# ATA5272 device description
Architecture: AVR8; Family: megaAVR
Registers are 8-bit, access not given, no defined reset value unless marked. A register's access mark holds for its fields unless they carry their own. Offsets are from the block's base; [hi:lo] are bit positions.

## FUSE
Instances: FUSE 0 in fuses
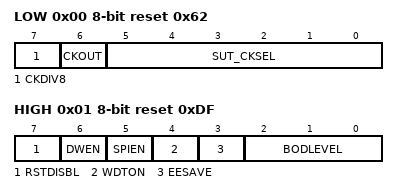
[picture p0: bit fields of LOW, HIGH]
0x00 LOW reset 0x62
  [7] CKDIV8 — Divide clock by 8 internally
  [6] CKOUT — Clock output on PORTB5
  [5:0] SUT_CKSEL — Select Clock source
    0=EXT_CLOCK_START_UP_TIME_PWRDWN_RESET_6_CK_14_CK_0_MS; 16=EXT_CLOCK_START_UP_TIME_PWRDWN_RESET_6_CK_14_CK_4_MS; 32=EXT_CLOCK_START_UP_TIME_PWRDWN_RESET_6_CK_14_CK_64_MS; 2=INT_RC_OSC_8_MHZ_START_UP_TIME_PWRDWN_RESET_6_CK_14_CK_0_MS; 18=INT_RC_OSC_8_MHZ_START_UP_TIME_PWRDWN_RESET_6_CK_14_CK_4_MS; 34=INT_RC_OSC_8_MHZ_START_UP_TIME_PWRDWN_RESET_6_CK_14_CK_64_MS; 3=WD_OSC_128_KHZ_START_UP_TIME_PWRDWN_RESET_6_CK_14_CK_0_MS; 19=WD_OSC_128_KHZ_START_UP_TIME_PWRDWN_RESET_6_CK_14_CK_4_MS; 35=WD_OSC_128_KHZ_START_UP_TIME_PWRDWN_RESET_6_CK_14_CK_64_MS; 4=EXT_LOW_FREQ_CRYSTAL_START_UP_TIME_PWRDWN_RESET_1024_CK_4_MS; 20=EXT_LOW_FREQ_CRYSTAL_START_UP_TIME_PWRDWN_RESET_1024_CK_64_MS; 36=EXT_LOW_FREQ_CRYSTAL_START_UP_TIME_PWRDWN_RESET_32768_CK_64_MS; 8=EXT_CERAMIC_RES_0_4_0_9_MHZ_START_UP_TIME_PWRDWN_RESET_258_CK_14_CK_4_1_MS; 24=EXT_CERAMIC_RES_0_4_0_9_MHZ_START_UP_TIME_PWRDWN_RESET_258_CK_14_CK_65_MS; 40=EXT_CERAMIC_RES_0_4_0_9_MHZ_START_UP_TIME_PWRDWN_RESET_1024_CK_14_CK_0_MS; 56=EXT_CERAMIC_RES_0_4_0_9_MHZ_START_UP_TIME_PWRDWN_RESET_1024_CK_14_CK_4_1_MS; 9=EXT_CERAMIC_RES_0_4_0_9_MHZ_START_UP_TIME_PWRDWN_RESET_1024_CK_14_CK_65_MS; 25=EXT_CRYSTAL_OSC_0_4_0_9_MHZ_START_UP_TIME_PWRDWN_RESET_16384_CK_14_CK_0_MS; 41=EXT_CRYSTAL_OSC_0_4_0_9_MHZ_START_UP_TIME_PWRDWN_RESET_16384_CK_14_CK_4_1_MS; 57=EXT_CRYSTAL_OSC_0_4_0_9_MHZ_START_UP_TIME_PWRDWN_RESET_16384_CK_14_CK_65_MS; 10=EXT_CERAMIC_RES_0_9_3_0_MHZ_START_UP_TIME_PWRDWN_RESET_258_CK_14_CK_4_1_MS; 26=EXT_CERAMIC_RES_0_9_3_0_MHZ_START_UP_TIME_PWRDWN_RESET_258_CK_14_CK_65_MS; 42=EXT_CERAMIC_RES_0_9_3_0_MHZ_START_UP_TIME_PWRDWN_RESET_1024_CK_14_CK_0_MS; 58=EXT_CERAMIC_RES_0_9_3_0_MHZ_START_UP_TIME_PWRDWN_RESET_1024_CK_14_CK_4_1_MS; 11=EXT_CERAMIC_RES_0_9_3_0_MHZ_START_UP_TIME_PWRDWN_RESET_1024_CK_14_CK_65_MS; 27=EXT_CRYSTAL_OSC_0_9_3_0_MHZ_START_UP_TIME_PWRDWN_RESET_16384_CK_14_CK_0_MS; 43=EXT_CRYSTAL_OSC_0_9_3_0_MHZ_START_UP_TIME_PWRDWN_RESET_16384_CK_14_CK_4_1_MS; 59=EXT_CRYSTAL_OSC_0_9_3_0_MHZ_START_UP_TIME_PWRDWN_RESET_16384_CK_14_CK_65_MS; 12=EXT_CERAMIC_RES_3_0_8_0_MHZ_START_UP_TIME_PWRDWN_RESET_258_CK_14_CK_4_1_MS; 28=EXT_CERAMIC_RES_3_0_8_0_MHZ_START_UP_TIME_PWRDWN_RESET_258_CK_14_CK_65_MS; 44=EXT_CERAMIC_RES_3_0_8_0_MHZ_START_UP_TIME_PWRDWN_RESET_1024_CK_14_CK_0_MS; 60=EXT_CERAMIC_RES_3_0_8_0_MHZ_START_UP_TIME_PWRDWN_RESET_1024_CK_14_CK_4_1_MS; 13=EXT_CERAMIC_RES_3_0_8_0_MHZ_START_UP_TIME_PWRDWN_RESET_1024_CK_14_CK_65_MS; 29=EXT_CRYSTAL_OSC_3_0_8_0_MHZ_START_UP_TIME_PWRDWN_RESET_16384_CK_14_CK_0_MS; 45=EXT_CRYSTAL_OSC_3_0_8_0_MHZ_START_UP_TIME_PWRDWN_RESET_16384_CK_14_CK_4_1_MS; 61=EXT_CRYSTAL_OSC_3_0_8_0_MHZ_START_UP_TIME_PWRDWN_RESET_16384_CK_14_CK_65_MS; 14=EXT_CERAMIC_RES_8_0_16_0_MHZ_START_UP_TIME_PWRDWN_RESET_258_CK_14_CK_4_1_MS; 30=EXT_CERAMIC_RES_8_0_16_0_MHZ_START_UP_TIME_PWRDWN_RESET_258_CK_14_CK_65_MS; 46=EXT_CERAMIC_RES_8_0_16_0_MHZ_START_UP_TIME_PWRDWN_RESET_1024_CK_14_CK_0_MS; 62=EXT_CERAMIC_RES_8_0_16_0_MHZ_START_UP_TIME_PWRDWN_RESET_1024_CK_14_CK_4_1_MS; 15=EXT_CERAMIC_RES_8_0_16_0_MHZ_START_UP_TIME_PWRDWN_RESET_1024_CK_14_CK_65_MS; 31=EXT_CRYSTAL_OSC_8_0_16_0_MHZ_START_UP_TIME_PWRDWN_RESET_16384_CK_14_CK_0_MS; 47=EXT_CRYSTAL_OSC_8_0_16_0_MHZ_START_UP_TIME_PWRDWN_RESET_16384_CK_14_CK_4_1_MS; 63=EXT_CRYSTAL_OSC_8_0_16_0_MHZ_START_UP_TIME_PWRDWN_RESET_16384_CK_14_CK_65_MS
0x01 HIGH reset 0xDF
  [7] RSTDISBL — Reset Disabled (Enable PB7 as i/o pin)
  [6] DWEN — Debug Wire enable
  [5] SPIEN — Serial program downloading (SPI) enabled
  [4] WDTON — Watch-dog Timer always ON
  [3] EESAVE — Preserve EEPROM through the Chip Erase cycle
  [2:0] BODLEVEL — Brown-out Detector trigger level
    4=BROWN_OUT_DETECTION_AT_VCC_4_3_V; 5=BROWN_OUT_DETECTION_AT_VCC_2_7_V; 6=BROWN_OUT_DETECTION_AT_VCC_1_8_V; 3=BROWN_OUT_DETECTION_AT_VCC_2_3_V; 2=BROWN_OUT_DETECTION_AT_VCC_2_2_V; 1=BROWN_OUT_DETECTION_AT_VCC_1_9_V; 0=BROWN_OUT_DETECTION_AT_VCC_2_0_V; 7=BROWN_OUT_DETECTION_DISABLED
0x02 EXTENDED reset 0xFF
  [0] SELFPRGEN — Self Programming enable
